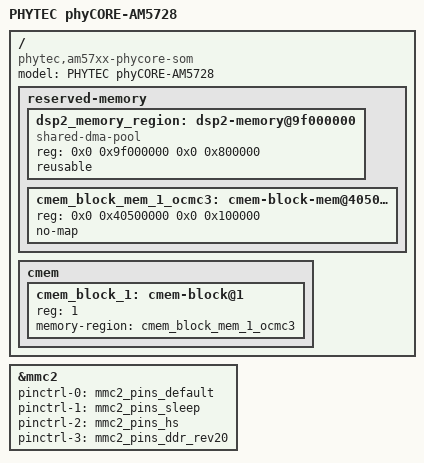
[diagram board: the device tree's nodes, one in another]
// SPDX-License-Identifier: GPL-2.0
/*
 * Copyright (C) 2023 PHYTEC Messtechnik GmbH
 * Author: Primoz Fiser <primoz.fiser@norik.com>
 */

#include "dra74x.dtsi"
#include "dra74x-mmc-iodelay.dtsi"
#include "am57xx-phycore-common.dtsi"

/ {
	model = "PHYTEC phyCORE-AM5728";
	compatible = "phytec,am57xx-phycore-som", "ti,am5728", "ti,dra742", "ti,dra74", "ti,dra7";

	reserved-memory {
		#address-cells = <2>;
		#size-cells = <2>;
		ranges;

		dsp2_memory_region: dsp2-memory@9f000000 {
			compatible = "shared-dma-pool";
			reg = <0x0 0x9f000000 0x0 0x800000>;
			reusable;
		};

		cmem_block_mem_1_ocmc3: cmem-block-mem@40500000 {
			reg = <0x0 0x40500000 0x0 0x100000>;
			no-map;
		};
	};

	cmem {
		cmem_block_1: cmem-block@1 {
			reg = <1>;
			memory-region = <&cmem_block_mem_1_ocmc3>;
		};
	};
};

&mmc2 {
	pinctrl-names = "default", "sleep", "hs", "ddr_3_3v";
	pinctrl-0 = <&mmc2_pins_default>;
	pinctrl-1 = <&mmc2_pins_sleep>;
	pinctrl-2 = <&mmc2_pins_hs>;
	pinctrl-3 = <&mmc2_pins_ddr_rev20>;
};
